# SYSCTRL_PADCONF_CORE register map
Vendor: Texas Instruments
Registers are 32-bit, access per field, reset 0x10F010F unless marked. A register's access mark holds for its fields unless they carry their own. Offsets are as the file gives them; [hi:lo] are bit positions; lines under a group give offsets from that group; {n}, {i} and the like mark numbered series; 'fields as' and 'values as' point back to an identical list.

## SYSCTRL_PADCONF_CORE (part 9 of 10)
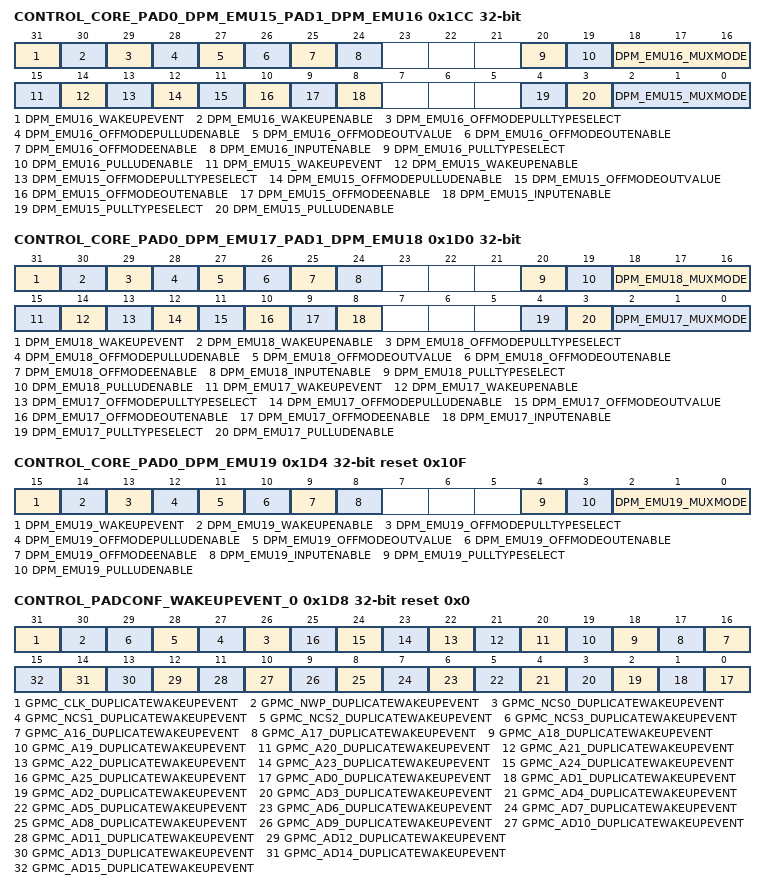
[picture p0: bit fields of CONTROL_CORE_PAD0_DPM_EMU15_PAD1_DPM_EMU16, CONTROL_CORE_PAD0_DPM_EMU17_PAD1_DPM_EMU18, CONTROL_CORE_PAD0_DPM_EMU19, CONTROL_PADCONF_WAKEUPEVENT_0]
0x1CC CONTROL_CORE_PAD0_DPM_EMU15_PAD1_DPM_EMU16 — Register control for Pads dpm_emu15 and dpm_emu16 Access conditions. Read: unrestricted, Write: unrestricted
  [31] DPM_EMU16_WAKEUPEVENT ro — Pad_x wake-up event status latched in the IO
    0=DPM_EMU16_WAKEUPEVENT_0_r (No wake-up event occurred); 1=DPM_EMU16_WAKEUPEVENT_1_r (A wake-up event occurred)
  [30] DPM_EMU16_WAKEUPENABLE rw — Input pad wake-up enable (and OFF mode input enable value)
    0=wake-up detection is disabled; 1=wake-up detection is enabled
  [29] DPM_EMU16_OFFMODEPULLTYPESELECT rw — OffMode mode pullup/down selection for pad dpm_emu16
    0=Offmode pulldown selected; 1=Offmode pullup selected
  [28] DPM_EMU16_OFFMODEPULLUDENABLE rw — OffMode mode pullup/down enable for pad dpm_emu16
    0=Offmode pullup/down disabled; 1=Offmode pullup/down enabled
  [27] DPM_EMU16_OFFMODEOUTVALUE rw — OffMode mode output value for pad dpm_emu16
    0=Set value at 0; 1=Set value at 1
  [26] DPM_EMU16_OFFMODEOUTENABLE rw — OffMode mode output enable value for pad dpm_emu16. This is an active low signal
    0=Output enable; 1=Output disable
  [25] DPM_EMU16_OFFMODEENABLE rw — OffMode mode override control for pad dpm_emu16
    0=I/O state keeps its previous state when OFF mode is active; 1=I/O state is forced to OFF mode value when OFF mode is active
  [24] DPM_EMU16_INPUTENABLE rw — Input enable value for pad dpm_emu16
    0=Input buffer of I/O cell is disabled; 1=Input buffer of I/O cell is enabled
  [20] DPM_EMU16_PULLTYPESELECT rw — pullup/down selection for pad dpm_emu16
    0=pulldown selected; 1=pullup selected
  [19] DPM_EMU16_PULLUDENABLE rw — pullup/down enable for pad dpm_emu16
    0=pullup/down disabled; 1=pullup/down enabled
  [18:16] DPM_EMU16_MUXMODE rw — Functional multiplexing selection for pad dpm_emu16
    0=Select dpm_emu16; 1=Select dmtimer8_pwm_evt; 2=Select dsi1_te0; 3=Select gpio_27; 4=Select rfbi_data3; 5=Select dispc2_data3; 6=Select hw_dbg16; 7=Select safe_mode
  [15] DPM_EMU15_WAKEUPEVENT ro — Pad_x wake-up event status latched in the IO
    0=DPM_EMU15_WAKEUPEVENT_0_r (No wake-up event occurred); 1=DPM_EMU15_WAKEUPEVENT_1_r (A wake-up event occurred)
  [14] DPM_EMU15_WAKEUPENABLE rw — Input pad wake-up enable (and OFF mode input enable value)
    values as DPM_EMU16_WAKEUPENABLE
  [13] DPM_EMU15_OFFMODEPULLTYPESELECT rw — OffMode mode pullup/down selection for pad dpm_emu15
    0=Offmode pulldown selected; 1=Offmode pullup selected
  [12] DPM_EMU15_OFFMODEPULLUDENABLE rw — OffMode mode pullup/down enable for pad dpm_emu15
    values as DPM_EMU16_OFFMODEPULLUDENABLE
  [11] DPM_EMU15_OFFMODEOUTVALUE rw — OffMode mode output value for pad dpm_emu15
    0=Set value at 0; 1=Set value at 1
  [10] DPM_EMU15_OFFMODEOUTENABLE rw — OffMode mode output enable value for pad dpm_emu15. This is an active low signal
    0=Output enable; 1=Output disable
  [9] DPM_EMU15_OFFMODEENABLE rw — OffMode mode override control for pad dpm_emu15
    values as DPM_EMU16_OFFMODEENABLE
  [8] DPM_EMU15_INPUTENABLE rw — Input enable value for pad dpm_emu15
    values as DPM_EMU16_INPUTENABLE
  [4] DPM_EMU15_PULLTYPESELECT rw — pullup/down selection for pad dpm_emu15
    0=pulldown selected; 1=pullup selected
  [3] DPM_EMU15_PULLUDENABLE rw — pullup/down enable for pad dpm_emu15
    0=pullup/down disabled; 1=pullup/down enabled
  [2:0] DPM_EMU15_MUXMODE rw — Functional multiplexing selection for pad dpm_emu15
    0=Select dpm_emu15; 3=Select gpio_26; 4=Select rfbi_data4; 5=Select dispc2_data4; 6=Select hw_dbg15; 7=Select safe_mode
0x1D0 CONTROL_CORE_PAD0_DPM_EMU17_PAD1_DPM_EMU18 — Register control for Pads dpm_emu17 and dpm_emu18 Access conditions. Read: unrestricted, Write: unrestricted
  [31] DPM_EMU18_WAKEUPEVENT ro — Pad_x wake-up event status latched in the IO
    0=DPM_EMU18_WAKEUPEVENT_0_r (No wake-up event occurred); 1=DPM_EMU18_WAKEUPEVENT_1_r (A wake-up event occurred)
  [30] DPM_EMU18_WAKEUPENABLE rw — Input pad wake-up enable (and OFF mode input enable value)
    values as CONTROL_CORE_PAD0_DPM_EMU15_PAD1_DPM_EMU16.DPM_EMU16_WAKEUPENABLE
  [29] DPM_EMU18_OFFMODEPULLTYPESELECT rw — OffMode mode pullup/down selection for pad dpm_emu18
    0=Offmode pulldown selected; 1=Offmode pullup selected
  [28] DPM_EMU18_OFFMODEPULLUDENABLE rw — OffMode mode pullup/down enable for pad dpm_emu18
    values as CONTROL_CORE_PAD0_DPM_EMU15_PAD1_DPM_EMU16.DPM_EMU16_OFFMODEPULLUDENABLE
  [27] DPM_EMU18_OFFMODEOUTVALUE rw — OffMode mode output value for pad dpm_emu18
    0=Set value at 0; 1=Set value at 1
  [26] DPM_EMU18_OFFMODEOUTENABLE rw — OffMode mode output enable value for pad dpm_emu18. This is an active low signal
    0=Output enable; 1=Output disable
  [25] DPM_EMU18_OFFMODEENABLE rw — OffMode mode override control for pad dpm_emu18
    values as CONTROL_CORE_PAD0_DPM_EMU15_PAD1_DPM_EMU16.DPM_EMU16_OFFMODEENABLE
  [24] DPM_EMU18_INPUTENABLE rw — Input enable value for pad dpm_emu18
    values as CONTROL_CORE_PAD0_DPM_EMU15_PAD1_DPM_EMU16.DPM_EMU16_INPUTENABLE
  [20] DPM_EMU18_PULLTYPESELECT rw — pullup/down selection for pad dpm_emu18
    0=pulldown selected; 1=pullup selected
  [19] DPM_EMU18_PULLUDENABLE rw — pullup/down enable for pad dpm_emu18
    0=pullup/down disabled; 1=pullup/down enabled
  [18:16] DPM_EMU18_MUXMODE rw — Functional multiplexing selection for pad dpm_emu18
    0=Select dpm_emu18; 1=Select dmtimer10_pwm_evt; 2=Select dsi2_te0; 3=Select gpio_190; 4=Select rfbi_data1; 5=Select dispc2_data1; 6=Select hw_dbg18; 7=Select safe_mode
  [15] DPM_EMU17_WAKEUPEVENT ro — Pad_x wake-up event status latched in the IO
    0=DPM_EMU17_WAKEUPEVENT_0_r (No wake-up event occurred); 1=DPM_EMU17_WAKEUPEVENT_1_r (A wake-up event occurred)
  [14] DPM_EMU17_WAKEUPENABLE rw — Input pad wake-up enable (and OFF mode input enable value)
    values as CONTROL_CORE_PAD0_DPM_EMU15_PAD1_DPM_EMU16.DPM_EMU16_WAKEUPENABLE
  [13] DPM_EMU17_OFFMODEPULLTYPESELECT rw — OffMode mode pullup/down selection for pad dpm_emu17
    0=Offmode pulldown selected; 1=Offmode pullup selected
  [12] DPM_EMU17_OFFMODEPULLUDENABLE rw — OffMode mode pullup/down enable for pad dpm_emu17
    values as CONTROL_CORE_PAD0_DPM_EMU15_PAD1_DPM_EMU16.DPM_EMU16_OFFMODEPULLUDENABLE
  [11] DPM_EMU17_OFFMODEOUTVALUE rw — OffMode mode output value for pad dpm_emu17
    0=Set value at 0; 1=Set value at 1
  [10] DPM_EMU17_OFFMODEOUTENABLE rw — OffMode mode output enable value for pad dpm_emu17. This is an active low signal
    0=Output enable; 1=Output disable
  [9] DPM_EMU17_OFFMODEENABLE rw — OffMode mode override control for pad dpm_emu17
    values as CONTROL_CORE_PAD0_DPM_EMU15_PAD1_DPM_EMU16.DPM_EMU16_OFFMODEENABLE
  [8] DPM_EMU17_INPUTENABLE rw — Input enable value for pad dpm_emu17
    values as CONTROL_CORE_PAD0_DPM_EMU15_PAD1_DPM_EMU16.DPM_EMU16_INPUTENABLE
  [4] DPM_EMU17_PULLTYPESELECT rw — pullup/down selection for pad dpm_emu17
    0=pulldown selected; 1=pullup selected
  [3] DPM_EMU17_PULLUDENABLE rw — pullup/down enable for pad dpm_emu17
    0=pullup/down disabled; 1=pullup/down enabled
  [2:0] DPM_EMU17_MUXMODE rw — Functional multiplexing selection for pad dpm_emu17
    0=Select dpm_emu17; 1=Select dmtimer9_pwm_evt; 2=Select dsi1_te1; 3=Select gpio_28; 4=Select rfbi_data2; 5=Select dispc2_data2; 6=Select hw_dbg17; 7=Select safe_mode
0x1D4 CONTROL_CORE_PAD0_DPM_EMU19 reset 0x10F — Register control for Pad dpm_emu19 Access conditions. Read: unrestricted, Write: unrestricted
  [15] DPM_EMU19_WAKEUPEVENT ro — Pad_x wake-up event status latched in the IO
    0=DPM_EMU19_WAKEUPEVENT_0_r (No wake-up event occurred); 1=DPM_EMU19_WAKEUPEVENT_1_r (A wake-up event occurred)
  [14] DPM_EMU19_WAKEUPENABLE rw — Input pad wake-up enable (and OFF mode input enable value)
    values as CONTROL_CORE_PAD0_DPM_EMU15_PAD1_DPM_EMU16.DPM_EMU16_WAKEUPENABLE
  [13] DPM_EMU19_OFFMODEPULLTYPESELECT rw — OffMode mode pullup/down selection for pad dpm_emu19
    0=Offmode pulldown selected; 1=Offmode pullup selected
  [12] DPM_EMU19_OFFMODEPULLUDENABLE rw — OffMode mode pullup/down enable for pad dpm_emu19
    values as CONTROL_CORE_PAD0_DPM_EMU15_PAD1_DPM_EMU16.DPM_EMU16_OFFMODEPULLUDENABLE
  [11] DPM_EMU19_OFFMODEOUTVALUE rw — OffMode mode output value for pad dpm_emu19
    0=Set value at 0; 1=Set value at 1
  [10] DPM_EMU19_OFFMODEOUTENABLE rw — OffMode mode output enable value for pad dpm_emu19. This is an active low signal
    0=Output enable; 1=Output disable
  [9] DPM_EMU19_OFFMODEENABLE rw — OffMode mode override control for pad dpm_emu19
    values as CONTROL_CORE_PAD0_DPM_EMU15_PAD1_DPM_EMU16.DPM_EMU16_OFFMODEENABLE
  [8] DPM_EMU19_INPUTENABLE rw — Input enable value for pad dpm_emu19
    values as CONTROL_CORE_PAD0_DPM_EMU15_PAD1_DPM_EMU16.DPM_EMU16_INPUTENABLE
  [4] DPM_EMU19_PULLTYPESELECT rw — pullup/down selection for pad dpm_emu19
    0=pulldown selected; 1=pullup selected
  [3] DPM_EMU19_PULLUDENABLE rw — pullup/down enable for pad dpm_emu19
    0=pullup/down disabled; 1=pullup/down enabled
  [2:0] DPM_EMU19_MUXMODE rw — Functional multiplexing selection for pad dpm_emu19
    0=Select dpm_emu19; 1=Select dmtimer11_pwm_evt; 2=Select dsi2_te1; 3=Select gpio_191; 4=Select rfbi_data0; 5=Select dispc2_data0; 6=Select hw_dbg19; 7=Select safe_mode
0x1D8 CONTROL_PADCONF_WAKEUPEVENT_0 ro reset 0x0 — Access conditions. Read: unrestricted, Write: unrestricted
  [31] GPMC_CLK_DUPLICATEWAKEUPEVENT — Wake-up event status latched in the I/O for pad gpmc_clk
    0=GPMC_CLK_DUPLICATEWAKEUPEVENT_0_r (No wake-up event occurred); 1=GPMC_CLK_DUPLICATEWAKEUPEVENT_1_r (A wake-up event occurred)
  [30] GPMC_NWP_DUPLICATEWAKEUPEVENT — Wake-up event status latched in the I/O for pad gpmc_nwp
    0=GPMC_NWP_DUPLICATEWAKEUPEVENT_0_r (No wake-up event occurred); 1=GPMC_NWP_DUPLICATEWAKEUPEVENT_1_r (A wake-up event occurred)
  [n+26] GPMC_NCS{n}_DUPLICATEWAKEUPEVENT (n=0..3) — Wake-up event status latched in the I/O for pad gpmc_ncs{n}
    0=GPMC_NCS{n}_DUPLICATEWAKEUPEVENT_0_r (No wake-up event occurred); 1=GPMC_NCS{n}_DUPLICATEWAKEUPEVENT_1_r (A wake-up event occurred)
  [n] GPMC_A{n}_DUPLICATEWAKEUPEVENT (n=16..25) — Wake-up event status latched in the I/O for pad gpmc_a{n}
    0=GPMC_A{n}_DUPLICATEWAKEUPEVENT_0_r (No wake-up event occurred); 1=GPMC_A{n}_DUPLICATEWAKEUPEVENT_1_r (A wake-up event occurred)
  [n] GPMC_AD{n}_DUPLICATEWAKEUPEVENT (n=0..15) — Wake-up event status latched in the I/O for pad gpmc_ad{n}
    0=GPMC_AD{n}_DUPLICATEWAKEUPEVENT_0_r (No wake-up event occurred); 1=GPMC_AD{n}_DUPLICATEWAKEUPEVENT_1_r (A wake-up event occurred)
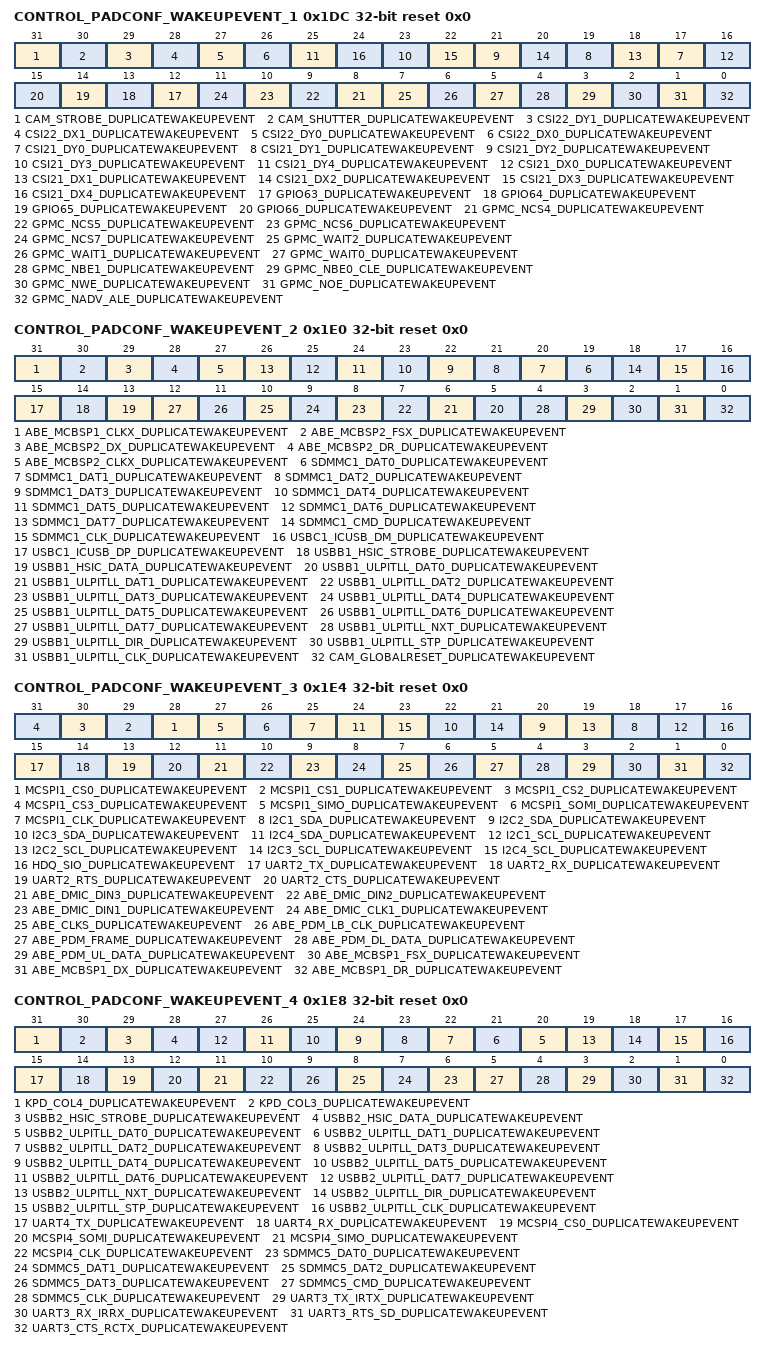
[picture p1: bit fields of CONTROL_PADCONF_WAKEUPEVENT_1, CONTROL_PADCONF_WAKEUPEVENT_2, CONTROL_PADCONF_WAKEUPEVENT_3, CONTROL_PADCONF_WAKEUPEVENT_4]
0x1DC CONTROL_PADCONF_WAKEUPEVENT_1 ro reset 0x0 — Access conditions. Read: unrestricted, Write: unrestricted
  [31] CAM_STROBE_DUPLICATEWAKEUPEVENT — Wake-up event status latched in the I/O for pad cam_strobe
    0=CAM_STROBE_DUPLICATEWAKEUPEVENT_0_r (No wake-up event occurred); 1=CAM_STROBE_DUPLICATEWAKEUPEVENT_1_r (A wake-up event occurred)
  [30] CAM_SHUTTER_DUPLICATEWAKEUPEVENT — Wake-up event status latched in the I/O for pad cam_shutter
    0=CAM_SHUTTER_DUPLICATEWAKEUPEVENT_0_r (No wake-up event occurred); 1=CAM_SHUTTER_DUPLICATEWAKEUPEVENT_1_r (A wake-up event occurred)
  [29] CSI22_DY1_DUPLICATEWAKEUPEVENT — Wake-up event status latched in the I/O for pad csi22_dy1
    0=CSI22_DY1_DUPLICATEWAKEUPEVENT_0_r (No wake-up event occurred); 1=CSI22_DY1_DUPLICATEWAKEUPEVENT_1_r (A wake-up event occurred)
  [28] CSI22_DX1_DUPLICATEWAKEUPEVENT — Wake-up event status latched in the I/O for pad csi22_dx1
    0=CSI22_DX1_DUPLICATEWAKEUPEVENT_0_r (No wake-up event occurred); 1=CSI22_DX1_DUPLICATEWAKEUPEVENT_1_r (A wake-up event occurred)
  [27] CSI22_DY0_DUPLICATEWAKEUPEVENT — Wake-up event status latched in the I/O for pad csi22_dy0
    0=CSI22_DY0_DUPLICATEWAKEUPEVENT_0_r (No wake-up event occurred); 1=CSI22_DY0_DUPLICATEWAKEUPEVENT_1_r (A wake-up event occurred)
  [26] CSI22_DX0_DUPLICATEWAKEUPEVENT — Wake-up event status latched in the I/O for pad csi22_dx0
    0=CSI22_DX0_DUPLICATEWAKEUPEVENT_0_r (No wake-up event occurred); 1=CSI22_DX0_DUPLICATEWAKEUPEVENT_1_r (A wake-up event occurred)
  [2n+17] CSI21_DY{n}_DUPLICATEWAKEUPEVENT (n=0..4) — Wake-up event status latched in the I/O for pad csi21_dy{n}
    0=CSI21_DY{n}_DUPLICATEWAKEUPEVENT_0_r (No wake-up event occurred); 1=CSI21_DY{n}_DUPLICATEWAKEUPEVENT_1_r (A wake-up event occurred)
  [2n+16] CSI21_DX{n}_DUPLICATEWAKEUPEVENT (n=0..4) — Wake-up event status latched in the I/O for pad csi21_dx{n}
    0=CSI21_DX{n}_DUPLICATEWAKEUPEVENT_0_r (No wake-up event occurred); 1=CSI21_DX{n}_DUPLICATEWAKEUPEVENT_1_r (A wake-up event occurred)
  [n-51] GPIO{n}_DUPLICATEWAKEUPEVENT (n=63..66) — Wake-up event status latched in the I/O for pad gpio{n}
    0=GPIO{n}_DUPLICATEWAKEUPEVENT_0_r (No wake-up event occurred); 1=GPIO{n}_DUPLICATEWAKEUPEVENT_1_r (A wake-up event occurred)
  [n+4] GPMC_NCS{n}_DUPLICATEWAKEUPEVENT (n=4..7) — Wake-up event status latched in the I/O for pad gpmc_ncs{n}
    values as CONTROL_PADCONF_WAKEUPEVENT_0.GPMC_NCS0_DUPLICATEWAKEUPEVENT
  [7] GPMC_WAIT2_DUPLICATEWAKEUPEVENT — Wake-up event status latched in the I/O for pad gpmc_wait2
    0=GPMC_WAIT2_DUPLICATEWAKEUPEVENT_0_r (No wake-up event occurred); 1=GPMC_WAIT2_DUPLICATEWAKEUPEVENT_1_r (A wake-up event occurred)
  [6] GPMC_WAIT1_DUPLICATEWAKEUPEVENT — Wake-up event status latched in the I/O for pad gpmc_wait1
    0=GPMC_WAIT1_DUPLICATEWAKEUPEVENT_0_r (No wake-up event occurred); 1=GPMC_WAIT1_DUPLICATEWAKEUPEVENT_1_r (A wake-up event occurred)
  [5] GPMC_WAIT0_DUPLICATEWAKEUPEVENT — Wake-up event status latched in the I/O for pad gpmc_wait0
    0=GPMC_WAIT0_DUPLICATEWAKEUPEVENT_0_r (No wake-up event occurred); 1=GPMC_WAIT0_DUPLICATEWAKEUPEVENT_1_r (A wake-up event occurred)
  [4] GPMC_NBE1_DUPLICATEWAKEUPEVENT — Wake-up event status latched in the I/O for pad gpmc_nbe1
    0=GPMC_NBE1_DUPLICATEWAKEUPEVENT_0_r (No wake-up event occurred); 1=GPMC_NBE1_DUPLICATEWAKEUPEVENT_1_r (A wake-up event occurred)
  [3] GPMC_NBE0_CLE_DUPLICATEWAKEUPEVENT — Wake-up event status latched in the I/O for pad gpmc_nbe0_cle
    0=GPMC_NBE0_CLE_DUPLICATEWAKEUPEVENT_0_r (No wake-up event occurred); 1=GPMC_NBE0_CLE_DUPLICATEWAKEUPEVENT_1_r (A wake-up event occurred)
  [2] GPMC_NWE_DUPLICATEWAKEUPEVENT — Wake-up event status latched in the I/O for pad gpmc_nwe
    0=GPMC_NWE_DUPLICATEWAKEUPEVENT_0_r (No wake-up event occurred); 1=GPMC_NWE_DUPLICATEWAKEUPEVENT_1_r (A wake-up event occurred)
  [1] GPMC_NOE_DUPLICATEWAKEUPEVENT — Wake-up event status latched in the I/O for pad gpmc_noe
    0=GPMC_NOE_DUPLICATEWAKEUPEVENT_0_r (No wake-up event occurred); 1=GPMC_NOE_DUPLICATEWAKEUPEVENT_1_r (A wake-up event occurred)
  [0] GPMC_NADV_ALE_DUPLICATEWAKEUPEVENT — Wake-up event status latched in the I/O for pad gpmc_nadv_ale
    0=GPMC_NADV_ALE_DUPLICATEWAKEUPEVENT_0_r (No wake-up event occurred); 1=GPMC_NADV_ALE_DUPLICATEWAKEUPEVENT_1_r (A wake-up event occurred)
0x1E0 CONTROL_PADCONF_WAKEUPEVENT_2 ro reset 0x0 — Access conditions. Read: unrestricted, Write: unrestricted
  [31] ABE_MCBSP1_CLKX_DUPLICATEWAKEUPEVENT — Wake-up event status latched in the I/O for pad abe_mcbsp1_clkx
    0=ABE_MCBSP1_CLKX_DUPLICATEWAKEUPEVENT_0_r (No wake-up event occurred); 1=ABE_MCBSP1_CLKX_DUPLICATEWAKEUPEVENT_1_r (A wake-up event occurred)
  [30] ABE_MCBSP2_FSX_DUPLICATEWAKEUPEVENT — Wake-up event status latched in the I/O for pad abe_mcbsp2_fsx
    0=ABE_MCBSP2_FSX_DUPLICATEWAKEUPEVENT_0_r (No wake-up event occurred); 1=ABE_MCBSP2_FSX_DUPLICATEWAKEUPEVENT_1_r (A wake-up event occurred)
  [29] ABE_MCBSP2_DX_DUPLICATEWAKEUPEVENT — Wake-up event status latched in the I/O for pad abe_mcbsp2_dx
    0=ABE_MCBSP2_DX_DUPLICATEWAKEUPEVENT_0_r (No wake-up event occurred); 1=ABE_MCBSP2_DX_DUPLICATEWAKEUPEVENT_1_r (A wake-up event occurred)
  [28] ABE_MCBSP2_DR_DUPLICATEWAKEUPEVENT — Wake-up event status latched in the I/O for pad abe_mcbsp2_dr
    0=ABE_MCBSP2_DR_DUPLICATEWAKEUPEVENT_0_r (No wake-up event occurred); 1=ABE_MCBSP2_DR_DUPLICATEWAKEUPEVENT_1_r (A wake-up event occurred)
  [27] ABE_MCBSP2_CLKX_DUPLICATEWAKEUPEVENT — Wake-up event status latched in the I/O for pad abe_mcbsp2_clkx
    0=ABE_MCBSP2_CLKX_DUPLICATEWAKEUPEVENT_0_r (No wake-up event occurred); 1=ABE_MCBSP2_CLKX_DUPLICATEWAKEUPEVENT_1_r (A wake-up event occurred)
  [n+19] SDMMC1_DAT{n}_DUPLICATEWAKEUPEVENT (n=0..7) — Wake-up event status latched in the I/O for pad sdmmc1_dat{n}
    0=SDMMC1_DAT{n}_DUPLICATEWAKEUPEVENT_0_r (No wake-up event occurred); 1=SDMMC1_DAT{n}_DUPLICATEWAKEUPEVENT_1_r (A wake-up event occurred)
  [18] SDMMC1_CMD_DUPLICATEWAKEUPEVENT — Wake-up event status latched in the I/O for pad sdmmc1_cmd
    0=SDMMC1_CMD_DUPLICATEWAKEUPEVENT_0_r (No wake-up event occurred); 1=SDMMC1_CMD_DUPLICATEWAKEUPEVENT_1_r (A wake-up event occurred)
  [17] SDMMC1_CLK_DUPLICATEWAKEUPEVENT — Wake-up event status latched in the I/O for pad sdmmc1_clk
    0=SDMMC1_CLK_DUPLICATEWAKEUPEVENT_0_r (No wake-up event occurred); 1=SDMMC1_CLK_DUPLICATEWAKEUPEVENT_1_r (A wake-up event occurred)
  [16] USBC1_ICUSB_DM_DUPLICATEWAKEUPEVENT — Wake-up event status latched in the I/O for pad usbc1_icusb_dm
    0=USBC1_ICUSB_DM_DUPLICATEWAKEUPEVENT_0_r (No wake-up event occurred); 1=USBC1_ICUSB_DM_DUPLICATEWAKEUPEVENT_1_r (A wake-up event occurred)
  [15] USBC1_ICUSB_DP_DUPLICATEWAKEUPEVENT — Wake-up event status latched in the I/O for pad usbc1_icusb_dp
    0=USBC1_ICUSB_DP_DUPLICATEWAKEUPEVENT_0_r (No wake-up event occurred); 1=USBC1_ICUSB_DP_DUPLICATEWAKEUPEVENT_1_r (A wake-up event occurred)
  [14] USBB1_HSIC_STROBE_DUPLICATEWAKEUPEVENT — Wake-up event status latched in the I/O for pad usbb1_hsic_strobe
    0=USBB1_HSIC_STROBE_DUPLICATEWAKEUPEVENT_0_r (No wake-up event occurred); 1=USBB1_HSIC_STROBE_DUPLICATEWAKEUPEVENT_1_r (A wake-up event occurred)
  [13] USBB1_HSIC_DATA_DUPLICATEWAKEUPEVENT — Wake-up event status latched in the I/O for pad usbb1_hsic_data
    0=USBB1_HSIC_DATA_DUPLICATEWAKEUPEVENT_0_r (No wake-up event occurred); 1=USBB1_HSIC_DATA_DUPLICATEWAKEUPEVENT_1_r (A wake-up event occurred)
  [n+5] USBB1_ULPITLL_DAT{n}_DUPLICATEWAKEUPEVENT (n=0..7) — Wake-up event status latched in the I/O for pad usbb1_ulpitll_dat{n}
    0=USBB1_ULPITLL_DAT{n}_DUPLICATEWAKEUPEVENT_0_r (No wake-up event occurred); 1=USBB1_ULPITLL_DAT{n}_DUPLICATEWAKEUPEVENT_1_r (A wake-up event occurred)
  [4] USBB1_ULPITLL_NXT_DUPLICATEWAKEUPEVENT — Wake-up event status latched in the I/O for pad usbb1_ulpitll_nxt
    0=USBB1_ULPITLL_NXT_DUPLICATEWAKEUPEVENT_0_r (No wake-up event occurred); 1=USBB1_ULPITLL_NXT_DUPLICATEWAKEUPEVENT_1_r (A wake-up event occurred)
  [3] USBB1_ULPITLL_DIR_DUPLICATEWAKEUPEVENT — Wake-up event status latched in the I/O for pad usbb1_ulpitll_dir
    0=USBB1_ULPITLL_DIR_DUPLICATEWAKEUPEVENT_0_r (No wake-up event occurred); 1=USBB1_ULPITLL_DIR_DUPLICATEWAKEUPEVENT_1_r (A wake-up event occurred)
  [2] USBB1_ULPITLL_STP_DUPLICATEWAKEUPEVENT — Wake-up event status latched in the I/O for pad usbb1_ulpitll_stp
    0=USBB1_ULPITLL_STP_DUPLICATEWAKEUPEVENT_0_r (No wake-up event occurred); 1=USBB1_ULPITLL_STP_DUPLICATEWAKEUPEVENT_1_r (A wake-up event occurred)
  [1] USBB1_ULPITLL_CLK_DUPLICATEWAKEUPEVENT — Wake-up event status latched in the I/O for pad usbb1_ulpitll_clk
    0=USBB1_ULPITLL_CLK_DUPLICATEWAKEUPEVENT_0_r (No wake-up event occurred); 1=USBB1_ULPITLL_CLK_DUPLICATEWAKEUPEVENT_1_r (A wake-up event occurred)
  [0] CAM_GLOBALRESET_DUPLICATEWAKEUPEVENT — Wake-up event status latched in the I/O for pad cam_globalreset
    0=CAM_GLOBALRESET_DUPLICATEWAKEUPEVENT_0_r (No wake-up event occurred); 1=CAM_GLOBALRESET_DUPLICATEWAKEUPEVENT_1_r (A wake-up event occurred)
0x1E4 CONTROL_PADCONF_WAKEUPEVENT_3 ro reset 0x0 — Access conditions. Read: unrestricted, Write: unrestricted
  [n+28] MCSPI1_CS{n}_DUPLICATEWAKEUPEVENT (n=0..3) — Wake-up event status latched in the I/O for pad mcspi1_cs{n}
    0=MCSPI1_CS{n}_DUPLICATEWAKEUPEVENT_0_r (No wake-up event occurred); 1=MCSPI1_CS{n}_DUPLICATEWAKEUPEVENT_1_r (A wake-up event occurred)
  [27] MCSPI1_SIMO_DUPLICATEWAKEUPEVENT — Wake-up event status latched in the I/O for pad mcspi1_simo
    0=MCSPI1_SIMO_DUPLICATEWAKEUPEVENT_0_r (No wake-up event occurred); 1=MCSPI1_SIMO_DUPLICATEWAKEUPEVENT_1_r (A wake-up event occurred)
  [26] MCSPI1_SOMI_DUPLICATEWAKEUPEVENT — Wake-up event status latched in the I/O for pad mcspi1_somi
    0=MCSPI1_SOMI_DUPLICATEWAKEUPEVENT_0_r (No wake-up event occurred); 1=MCSPI1_SOMI_DUPLICATEWAKEUPEVENT_1_r (A wake-up event occurred)
  [25] MCSPI1_CLK_DUPLICATEWAKEUPEVENT — Wake-up event status latched in the I/O for pad mcspi1_clk
    0=MCSPI1_CLK_DUPLICATEWAKEUPEVENT_0_r (No wake-up event occurred); 1=MCSPI1_CLK_DUPLICATEWAKEUPEVENT_1_r (A wake-up event occurred)
  [2n+16] I2C{n}_SDA_DUPLICATEWAKEUPEVENT (n=1..4) — Wake-up event status latched in the I/O for pad i2c{n}_sda
    0=I2C{n}_SDA_DUPLICATEWAKEUPEVENT_0_r (No wake-up event occurred); 1=I2C{n}_SDA_DUPLICATEWAKEUPEVENT_1_r (A wake-up event occurred)
  [2n+15] I2C{n}_SCL_DUPLICATEWAKEUPEVENT (n=1..4) — Wake-up event status latched in the I/O for pad i2c{n}_scl
    0=I2C{n}_SCL_DUPLICATEWAKEUPEVENT_0_r (No wake-up event occurred); 1=I2C{n}_SCL_DUPLICATEWAKEUPEVENT_1_r (A wake-up event occurred)
  [16] HDQ_SIO_DUPLICATEWAKEUPEVENT — Wake-up event status latched in the I/O for pad hdq_sio
    0=HDQ_SIO_DUPLICATEWAKEUPEVENT_0_r (No wake-up event occurred); 1=HDQ_SIO_DUPLICATEWAKEUPEVENT_1_r (A wake-up event occurred)
  [15] UART2_TX_DUPLICATEWAKEUPEVENT — Wake-up event status latched in the I/O for pad uart2_tx
    0=UART2_TX_DUPLICATEWAKEUPEVENT_0_r (No wake-up event occurred); 1=UART2_TX_DUPLICATEWAKEUPEVENT_1_r (A wake-up event occurred)
  [14] UART2_RX_DUPLICATEWAKEUPEVENT — Wake-up event status latched in the I/O for pad uart2_rx
    0=UART2_RX_DUPLICATEWAKEUPEVENT_0_r (No wake-up event occurred); 1=UART2_RX_DUPLICATEWAKEUPEVENT_1_r (A wake-up event occurred)
  [13] UART2_RTS_DUPLICATEWAKEUPEVENT — Wake-up event status latched in the I/O for pad uart2_rts
    0=UART2_RTS_DUPLICATEWAKEUPEVENT_0_r (No wake-up event occurred); 1=UART2_RTS_DUPLICATEWAKEUPEVENT_1_r (A wake-up event occurred)
  [12] UART2_CTS_DUPLICATEWAKEUPEVENT — Wake-up event status latched in the I/O for pad uart2_cts
    0=UART2_CTS_DUPLICATEWAKEUPEVENT_0_r (No wake-up event occurred); 1=UART2_CTS_DUPLICATEWAKEUPEVENT_1_r (A wake-up event occurred)
  [11] ABE_DMIC_DIN3_DUPLICATEWAKEUPEVENT — Wake-up event status latched in the I/O for pad abe_dmic_din3
    0=ABE_DMIC_DIN3_DUPLICATEWAKEUPEVENT_0_r (No wake-up event occurred); 1=ABE_DMIC_DIN3_DUPLICATEWAKEUPEVENT_1_r (A wake-up event occurred)
  [10] ABE_DMIC_DIN2_DUPLICATEWAKEUPEVENT — Wake-up event status latched in the I/O for pad abe_dmic_din2
    0=ABE_DMIC_DIN2_DUPLICATEWAKEUPEVENT_0_r (No wake-up event occurred); 1=ABE_DMIC_DIN2_DUPLICATEWAKEUPEVENT_1_r (A wake-up event occurred)
  [9] ABE_DMIC_DIN1_DUPLICATEWAKEUPEVENT — Wake-up event status latched in the I/O for pad abe_dmic_din1
    0=ABE_DMIC_DIN1_DUPLICATEWAKEUPEVENT_0_r (No wake-up event occurred); 1=ABE_DMIC_DIN1_DUPLICATEWAKEUPEVENT_1_r (A wake-up event occurred)
  [8] ABE_DMIC_CLK1_DUPLICATEWAKEUPEVENT — Wake-up event status latched in the I/O for pad abe_dmic_clk1
    0=ABE_DMIC_CLK1_DUPLICATEWAKEUPEVENT_0_r (No wake-up event occurred); 1=ABE_DMIC_CLK1_DUPLICATEWAKEUPEVENT_1_r (A wake-up event occurred)
  [7] ABE_CLKS_DUPLICATEWAKEUPEVENT — Wake-up event status latched in the I/O for pad abe_clks
    0=ABE_CLKS_DUPLICATEWAKEUPEVENT_0_r (No wake-up event occurred); 1=ABE_CLKS_DUPLICATEWAKEUPEVENT_1_r (A wake-up event occurred)
  [6] ABE_PDM_LB_CLK_DUPLICATEWAKEUPEVENT — Wake-up event status latched in the I/O for pad abe_pdm_lb_clk
    0=ABE_PDM_LB_CLK_DUPLICATEWAKEUPEVENT_0_r (No wake-up event occurred); 1=ABE_PDM_LB_CLK_DUPLICATEWAKEUPEVENT_1_r (A wake-up event occurred)
  [5] ABE_PDM_FRAME_DUPLICATEWAKEUPEVENT — Wake-up event status latched in the I/O for pad abe_pdm_frame
    0=ABE_PDM_FRAME_DUPLICATEWAKEUPEVENT_0_r (No wake-up event occurred); 1=ABE_PDM_FRAME_DUPLICATEWAKEUPEVENT_1_r (A wake-up event occurred)
  [4] ABE_PDM_DL_DATA_DUPLICATEWAKEUPEVENT — Wake-up event status latched in the I/O for pad abe_pdm_dl_data
    0=ABE_PDM_DL_DATA_DUPLICATEWAKEUPEVENT_0_r (No wake-up event occurred); 1=ABE_PDM_DL_DATA_DUPLICATEWAKEUPEVENT_1_r (A wake-up event occurred)
  [3] ABE_PDM_UL_DATA_DUPLICATEWAKEUPEVENT — Wake-up event status latched in the I/O for pad abe_pdm_ul_data
    0=ABE_PDM_UL_DATA_DUPLICATEWAKEUPEVENT_0_r (No wake-up event occurred); 1=ABE_PDM_UL_DATA_DUPLICATEWAKEUPEVENT_1_r (A wake-up event occurred)
  [2] ABE_MCBSP1_FSX_DUPLICATEWAKEUPEVENT — Wake-up event status latched in the I/O for pad abe_mcbsp1_fsx
    0=ABE_MCBSP1_FSX_DUPLICATEWAKEUPEVENT_0_r (No wake-up event occurred); 1=ABE_MCBSP1_FSX_DUPLICATEWAKEUPEVENT_1_r (A wake-up event occurred)
  [1] ABE_MCBSP1_DX_DUPLICATEWAKEUPEVENT — Wake-up event status latched in the I/O for pad abe_mcbsp1_dx
    0=ABE_MCBSP1_DX_DUPLICATEWAKEUPEVENT_0_r (No wake-up event occurred); 1=ABE_MCBSP1_DX_DUPLICATEWAKEUPEVENT_1_r (A wake-up event occurred)
  [0] ABE_MCBSP1_DR_DUPLICATEWAKEUPEVENT — Wake-up event status latched in the I/O for pad abe_mcbsp1_dr
    0=ABE_MCBSP1_DR_DUPLICATEWAKEUPEVENT_0_r (No wake-up event occurred); 1=ABE_MCBSP1_DR_DUPLICATEWAKEUPEVENT_1_r (A wake-up event occurred)
0x1E8 CONTROL_PADCONF_WAKEUPEVENT_4 ro reset 0x0 — Access conditions. Read: unrestricted, Write: unrestricted
  [31] KPD_COL4_DUPLICATEWAKEUPEVENT — Wake-up event status latched in the I/O for pad kpd_col4
    0=KPD_COL4_DUPLICATEWAKEUPEVENT_0_r (No wake-up event occurred); 1=KPD_COL4_DUPLICATEWAKEUPEVENT_1_r (A wake-up event occurred)
  [30] KPD_COL3_DUPLICATEWAKEUPEVENT — Wake-up event status latched in the I/O for pad kpd_col3
    0=KPD_COL3_DUPLICATEWAKEUPEVENT_0_r (No wake-up event occurred); 1=KPD_COL3_DUPLICATEWAKEUPEVENT_1_r (A wake-up event occurred)
  [29] USBB2_HSIC_STROBE_DUPLICATEWAKEUPEVENT — Wake-up event status latched in the I/O for pad usbb2_hsic_strobe
    0=USBB2_HSIC_STROBE_DUPLICATEWAKEUPEVENT_0_r (No wake-up event occurred); 1=USBB2_HSIC_STROBE_DUPLICATEWAKEUPEVENT_1_r (A wake-up event occurred)
  [28] USBB2_HSIC_DATA_DUPLICATEWAKEUPEVENT — Wake-up event status latched in the I/O for pad usbb2_hsic_data
    0=USBB2_HSIC_DATA_DUPLICATEWAKEUPEVENT_0_r (No wake-up event occurred); 1=USBB2_HSIC_DATA_DUPLICATEWAKEUPEVENT_1_r (A wake-up event occurred)
  [n+20] USBB2_ULPITLL_DAT{n}_DUPLICATEWAKEUPEVENT (n=0..7) — Wake-up event status latched in the I/O for pad usbb2_ulpitll_dat{n}
    0=USBB2_ULPITLL_DAT{n}_DUPLICATEWAKEUPEVENT_0_r (No wake-up event occurred); 1=USBB2_ULPITLL_DAT{n}_DUPLICATEWAKEUPEVENT_1_r (A wake-up event occurred)
  [19] USBB2_ULPITLL_NXT_DUPLICATEWAKEUPEVENT — Wake-up event status latched in the I/O for pad usbb2_ulpitll_nxt
    0=USBB2_ULPITLL_NXT_DUPLICATEWAKEUPEVENT_0_r (No wake-up event occurred); 1=USBB2_ULPITLL_NXT_DUPLICATEWAKEUPEVENT_1_r (A wake-up event occurred)
  [18] USBB2_ULPITLL_DIR_DUPLICATEWAKEUPEVENT — Wake-up event status latched in the I/O for pad usbb2_ulpitll_dir
    0=USBB2_ULPITLL_DIR_DUPLICATEWAKEUPEVENT_0_r (No wake-up event occurred); 1=USBB2_ULPITLL_DIR_DUPLICATEWAKEUPEVENT_1_r (A wake-up event occurred)
  [17] USBB2_ULPITLL_STP_DUPLICATEWAKEUPEVENT — Wake-up event status latched in the I/O for pad usbb2_ulpitll_stp
    0=USBB2_ULPITLL_STP_DUPLICATEWAKEUPEVENT_0_r (No wake-up event occurred); 1=USBB2_ULPITLL_STP_DUPLICATEWAKEUPEVENT_1_r (A wake-up event occurred)
  [16] USBB2_ULPITLL_CLK_DUPLICATEWAKEUPEVENT — Wake-up event status latched in the I/O for pad usbb2_ulpitll_clk
    0=USBB2_ULPITLL_CLK_DUPLICATEWAKEUPEVENT_0_r (No wake-up event occurred); 1=USBB2_ULPITLL_CLK_DUPLICATEWAKEUPEVENT_1_r (A wake-up event occurred)
  [15] UART4_TX_DUPLICATEWAKEUPEVENT — Wake-up event status latched in the I/O for pad uart4_tx
    0=UART4_TX_DUPLICATEWAKEUPEVENT_0_r (No wake-up event occurred); 1=UART4_TX_DUPLICATEWAKEUPEVENT_1_r (A wake-up event occurred)
  [14] UART4_RX_DUPLICATEWAKEUPEVENT — Wake-up event status latched in the I/O for pad uart4_rx
    0=UART4_RX_DUPLICATEWAKEUPEVENT_0_r (No wake-up event occurred); 1=UART4_RX_DUPLICATEWAKEUPEVENT_1_r (A wake-up event occurred)
  [13] MCSPI4_CS0_DUPLICATEWAKEUPEVENT — Wake-up event status latched in the I/O for pad mcspi4_cs0
    0=MCSPI4_CS0_DUPLICATEWAKEUPEVENT_0_r (No wake-up event occurred); 1=MCSPI4_CS0_DUPLICATEWAKEUPEVENT_1_r (A wake-up event occurred)
  [12] MCSPI4_SOMI_DUPLICATEWAKEUPEVENT — Wake-up event status latched in the I/O for pad mcspi4_somi
    0=MCSPI4_SOMI_DUPLICATEWAKEUPEVENT_0_r (No wake-up event occurred); 1=MCSPI4_SOMI_DUPLICATEWAKEUPEVENT_1_r (A wake-up event occurred)
  [11] MCSPI4_SIMO_DUPLICATEWAKEUPEVENT — Wake-up event status latched in the I/O for pad mcspi4_simo
    0=MCSPI4_SIMO_DUPLICATEWAKEUPEVENT_0_r (No wake-up event occurred); 1=MCSPI4_SIMO_DUPLICATEWAKEUPEVENT_1_r (A wake-up event occurred)
  [10] MCSPI4_CLK_DUPLICATEWAKEUPEVENT — Wake-up event status latched in the I/O for pad mcspi4_clk
    0=MCSPI4_CLK_DUPLICATEWAKEUPEVENT_0_r (No wake-up event occurred); 1=MCSPI4_CLK_DUPLICATEWAKEUPEVENT_1_r (A wake-up event occurred)
  [n+6] SDMMC5_DAT{n}_DUPLICATEWAKEUPEVENT (n=0..3) — Wake-up event status latched in the I/O for pad sdmmc5_dat{n}
    0=SDMMC5_DAT{n}_DUPLICATEWAKEUPEVENT_0_r (No wake-up event occurred); 1=SDMMC5_DAT{n}_DUPLICATEWAKEUPEVENT_1_r (A wake-up event occurred)
  [5] SDMMC5_CMD_DUPLICATEWAKEUPEVENT — Wake-up event status latched in the I/O for pad sdmmc5_cmd
    0=SDMMC5_CMD_DUPLICATEWAKEUPEVENT_0_r (No wake-up event occurred); 1=SDMMC5_CMD_DUPLICATEWAKEUPEVENT_1_r (A wake-up event occurred)
  [4] SDMMC5_CLK_DUPLICATEWAKEUPEVENT — Wake-up event status latched in the I/O for pad sdmmc5_clk
    0=SDMMC5_CLK_DUPLICATEWAKEUPEVENT_0_r (No wake-up event occurred); 1=SDMMC5_CLK_DUPLICATEWAKEUPEVENT_1_r (A wake-up event occurred)
  [3] UART3_TX_IRTX_DUPLICATEWAKEUPEVENT — Wake-up event status latched in the I/O for pad uart3_tx_irtx
    0=UART3_TX_IRTX_DUPLICATEWAKEUPEVENT_0_r (No wake-up event occurred); 1=UART3_TX_IRTX_DUPLICATEWAKEUPEVENT_1_r (A wake-up event occurred)
  [2] UART3_RX_IRRX_DUPLICATEWAKEUPEVENT — Wake-up event status latched in the I/O for pad uart3_rx_irrx
    0=UART3_RX_IRRX_DUPLICATEWAKEUPEVENT_0_r (No wake-up event occurred); 1=UART3_RX_IRRX_DUPLICATEWAKEUPEVENT_1_r (A wake-up event occurred)
  [1] UART3_RTS_SD_DUPLICATEWAKEUPEVENT — Wake-up event status latched in the I/O for pad uart3_rts_sd
    0=UART3_RTS_SD_DUPLICATEWAKEUPEVENT_0_r (No wake-up event occurred); 1=UART3_RTS_SD_DUPLICATEWAKEUPEVENT_1_r (A wake-up event occurred)
  [0] UART3_CTS_RCTX_DUPLICATEWAKEUPEVENT — Wake-up event status latched in the I/O for pad uart3_cts_rctx
    0=UART3_CTS_RCTX_DUPLICATEWAKEUPEVENT_0_r (No wake-up event occurred); 1=UART3_CTS_RCTX_DUPLICATEWAKEUPEVENT_1_r (A wake-up event occurred)
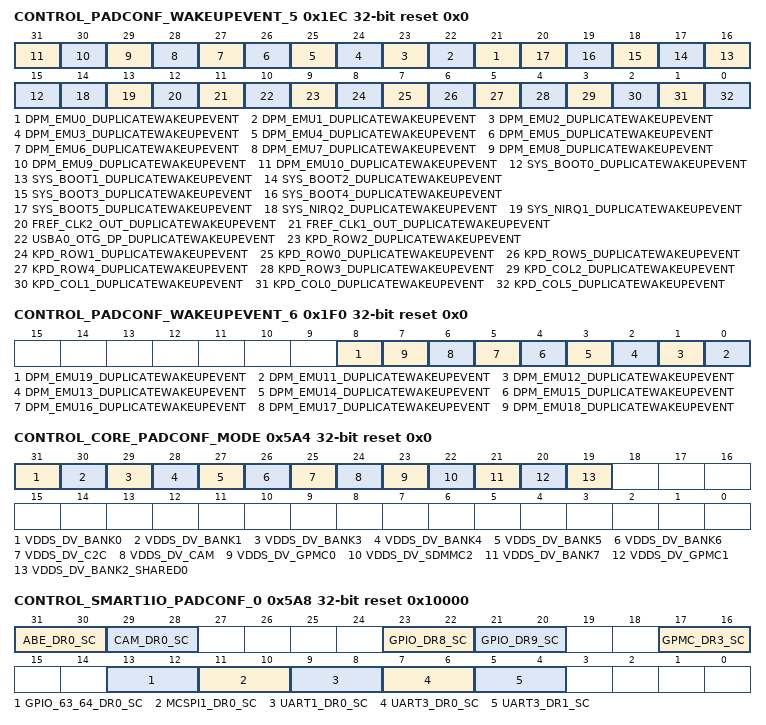
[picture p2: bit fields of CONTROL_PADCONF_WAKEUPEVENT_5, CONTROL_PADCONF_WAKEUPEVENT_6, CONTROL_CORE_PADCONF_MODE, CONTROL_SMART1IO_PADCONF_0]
0x1EC CONTROL_PADCONF_WAKEUPEVENT_5 ro reset 0x0 — Access conditions. Read: unrestricted, Write: unrestricted
  [n+21] DPM_EMU{n}_DUPLICATEWAKEUPEVENT (n=0..10) — Wake-up event status latched in the I/O for pad dpm_emu{n}
    0=DPM_EMU{n}_DUPLICATEWAKEUPEVENT_0_r (No wake-up event occurred); 1=DPM_EMU{n}_DUPLICATEWAKEUPEVENT_1_r (A wake-up event occurred)
  [n+15] SYS_BOOT{n}_DUPLICATEWAKEUPEVENT (n=0..5) — Wake-up event status latched in the I/O for pad sys_boot{n}
    0=SYS_BOOT{n}_DUPLICATEWAKEUPEVENT_0_r (No wake-up event occurred); 1=SYS_BOOT{n}_DUPLICATEWAKEUPEVENT_1_r (A wake-up event occurred)
  [14] SYS_NIRQ2_DUPLICATEWAKEUPEVENT — Wake-up event status latched in the I/O for pad sys_nirq2
    0=SYS_NIRQ2_DUPLICATEWAKEUPEVENT_0_r (No wake-up event occurred); 1=SYS_NIRQ2_DUPLICATEWAKEUPEVENT_1_r (A wake-up event occurred)
  [13] SYS_NIRQ1_DUPLICATEWAKEUPEVENT — Wake-up event status latched in the I/O for pad sys_nirq1
    0=SYS_NIRQ1_DUPLICATEWAKEUPEVENT_0_r (No wake-up event occurred); 1=SYS_NIRQ1_DUPLICATEWAKEUPEVENT_1_r (A wake-up event occurred)
  [12] FREF_CLK2_OUT_DUPLICATEWAKEUPEVENT — Wake-up event status latched in the I/O for pad fref_clk2_out
    0=FREF_CLK2_OUT_DUPLICATEWAKEUPEVENT_0_r (No wake-up event occurred); 1=FREF_CLK2_OUT_DUPLICATEWAKEUPEVENT_1_r (A wake-up event occurred)
  [11] FREF_CLK1_OUT_DUPLICATEWAKEUPEVENT — Wake-up event status latched in the I/O for pad fref_clk1_out
    0=FREF_CLK1_OUT_DUPLICATEWAKEUPEVENT_0_r (No wake-up event occurred); 1=FREF_CLK1_OUT_DUPLICATEWAKEUPEVENT_1_r (A wake-up event occurred)
  [10] USBA0_OTG_DP_DUPLICATEWAKEUPEVENT — Wake-up event status latched in the I/O for pad usba0_otg_dp
    0=USBA0_OTG_DP_DUPLICATEWAKEUPEVENT_0_r (No wake-up event occurred); 1=USBA0_OTG_DP_DUPLICATEWAKEUPEVENT_1_r (A wake-up event occurred)
  [9] KPD_ROW2_DUPLICATEWAKEUPEVENT — Wake-up event status latched in the I/O for pad kpd_row2
    0=KPD_ROW2_DUPLICATEWAKEUPEVENT_0_r (No wake-up event occurred); 1=KPD_ROW2_DUPLICATEWAKEUPEVENT_1_r (A wake-up event occurred)
  [8] KPD_ROW1_DUPLICATEWAKEUPEVENT — Wake-up event status latched in the I/O for pad kpd_row1
    0=KPD_ROW1_DUPLICATEWAKEUPEVENT_0_r (No wake-up event occurred); 1=KPD_ROW1_DUPLICATEWAKEUPEVENT_1_r (A wake-up event occurred)
  [7] KPD_ROW0_DUPLICATEWAKEUPEVENT — Wake-up event status latched in the I/O for pad kpd_row0
    0=KPD_ROW0_DUPLICATEWAKEUPEVENT_0_r (No wake-up event occurred); 1=KPD_ROW0_DUPLICATEWAKEUPEVENT_1_r (A wake-up event occurred)
  [6] KPD_ROW5_DUPLICATEWAKEUPEVENT — Wake-up event status latched in the I/O for pad kpd_row5
    0=KPD_ROW5_DUPLICATEWAKEUPEVENT_0_r (No wake-up event occurred); 1=KPD_ROW5_DUPLICATEWAKEUPEVENT_1_r (A wake-up event occurred)
  [5] KPD_ROW4_DUPLICATEWAKEUPEVENT — Wake-up event status latched in the I/O for pad kpd_row4
    0=KPD_ROW4_DUPLICATEWAKEUPEVENT_0_r (No wake-up event occurred); 1=KPD_ROW4_DUPLICATEWAKEUPEVENT_1_r (A wake-up event occurred)
  [4] KPD_ROW3_DUPLICATEWAKEUPEVENT — Wake-up event status latched in the I/O for pad kpd_row3
    0=KPD_ROW3_DUPLICATEWAKEUPEVENT_0_r (No wake-up event occurred); 1=KPD_ROW3_DUPLICATEWAKEUPEVENT_1_r (A wake-up event occurred)
  [3] KPD_COL2_DUPLICATEWAKEUPEVENT — Wake-up event status latched in the I/O for pad kpd_col2
    0=KPD_COL2_DUPLICATEWAKEUPEVENT_0_r (No wake-up event occurred); 1=KPD_COL2_DUPLICATEWAKEUPEVENT_1_r (A wake-up event occurred)
  [2] KPD_COL1_DUPLICATEWAKEUPEVENT — Wake-up event status latched in the I/O for pad kpd_col1
    0=KPD_COL1_DUPLICATEWAKEUPEVENT_0_r (No wake-up event occurred); 1=KPD_COL1_DUPLICATEWAKEUPEVENT_1_r (A wake-up event occurred)
  [1] KPD_COL0_DUPLICATEWAKEUPEVENT — Wake-up event status latched in the I/O for pad kpd_col0
    0=KPD_COL0_DUPLICATEWAKEUPEVENT_0_r (No wake-up event occurred); 1=KPD_COL0_DUPLICATEWAKEUPEVENT_1_r (A wake-up event occurred)
  [0] KPD_COL5_DUPLICATEWAKEUPEVENT — Wake-up event status latched in the I/O for pad kpd_col5
    0=KPD_COL5_DUPLICATEWAKEUPEVENT_0_r (No wake-up event occurred); 1=KPD_COL5_DUPLICATEWAKEUPEVENT_1_r (A wake-up event occurred)
0x1F0 CONTROL_PADCONF_WAKEUPEVENT_6 ro reset 0x0 — Access conditions. Read: unrestricted, Write: unrestricted
  [8] DPM_EMU19_DUPLICATEWAKEUPEVENT — Wake-up event status latched in the IO for pad dpm_emu19
    1=DPM_EMU19_DUPLICATEWAKEUPEVENT_1_r (A wakeup event occurred); 0=DPM_EMU19_DUPLICATEWAKEUPEVENT_0_r (No wakeup event occurred)
  [n-11] DPM_EMU{n}_DUPLICATEWAKEUPEVENT (n=11..18) — Wake-up event status latched in the I/O for pad dpm_emu{n}
    values as CONTROL_PADCONF_WAKEUPEVENT_5.DPM_EMU0_DUPLICATEWAKEUPEVENT
0x5A0 CONTROL_PADCONF_GLOBAL reset 0x0 — Global PAD control Access conditions. Read: unrestricted, Write: unrestricted
  [31] FORCE_OFFMODE_EN rw — Force offmode enable for PADs
    0=Offmode is not forced active; 1=Offmode is forced active
0x5A4 CONTROL_CORE_PADCONF_MODE reset 0x0 — PAD Voltage Mode control Access conditions. Read: unrestricted, Write: unrestricted
  [all] fields
    0=VDDS = 1.8V; 1=VDDS = 1.2V
  [31] VDDS_DV_BANK0 rw — PAD Voltage level control for vdds_dv_bank0
  [30] VDDS_DV_BANK1 rw — PAD Voltage level control for vdds_dv_bank1
  [32-n] VDDS_DV_BANK{n} rw (n=3..6) — PAD Voltage level control for vdds_dv_bank{n}
  [25] VDDS_DV_C2C rw — PAD Voltage level control for vdds_dv_c2c
  [24] VDDS_DV_CAM rw — PAD Voltage level control for vdds_dv_cam
  [23] VDDS_DV_GPMC0 rw — PAD Voltage level control for vdds_dv_gpmc0
  [22] VDDS_DV_SDMMC2 rw — PAD Voltage level control for vdds_dv_sdmmc2
  [21] VDDS_DV_BANK7 rw — PAD Voltage level control for vdds_dv_bank7
  [20] VDDS_DV_GPMC1 rw — PAD Voltage level control for vdds_dv_gpmc1
  [19] VDDS_DV_BANK2_SHARED0 rw — PAD Voltage level control for vdds_dv_bank2_shared0
0x5A8 CONTROL_SMART1IO_PADCONF_0 rw reset 0x10000 — SMART1 I/O control 0 Access conditions. Read: unrestricted, Write: unrestricted
  [31:30] ABE_DR0_SC — Slew rate control for group abe_dr0. Refer to , section Low Speed I/Os Combined Slew Rate vs TL Length and Load Settings for more details on SR settings.
  [29:28] CAM_DR0_SC — Slew rate control for group cam_dr0. Refer to , section Low Speed I/Os Combined Slew Rate vs TL Length and Load Settings for more details on SR settings.
  [23:22] GPIO_DR8_SC — Slew rate control for group gpio_dr8. Refer to , section Low Speed I/Os Combined Slew Rate vs TL Length and Load Settings for more details on SR settings.
  [21:20] GPIO_DR9_SC — Slew rate control for group gpio_dr9. Refer to , section Low Speed I/Os Combined Slew Rate vs TL Length and Load Settings for more details on SR settings.
  [17:16] GPMC_DR3_SC — Slew rate control for group gpmc_dr3. Refer to , section Low Speed I/Os Combined Slew Rate vs TL Length and Load Settings for more details on SR settings.
  [13:12] GPIO_63_64_DR0_SC — Slew rate control for group gpio_63_64_dr0. Refer to , section Low Speed I/Os Combined Slew Rate vs TL Length and Load Settings for more details on SR settings.
  [11:10] MCSPI1_DR0_SC — Slew rate control for group mcspi1_dr0 Refer to , section Low Speed I/Os Combined Slew Rate vs TL Length and Load Settings for more details on SR settings.
  [9:8] UART1_DR0_SC — Slew rate control for group uart1_dr0 Refer to , section Low Speed I/Os Combined Slew Rate vs TL Length and Load Settings for more details on SR settings.
  [7:6] UART3_DR0_SC — Slew rate control for group uart3_dr0 Refer to , section Low Speed I/Os Combined Slew Rate vs TL Length and Load Settings for more details on SR settings.
  [5:4] UART3_DR1_SC — Slew rate control for group uart3_dr1 Refer to , section Low Speed I/Os Combined Slew Rate vs TL Length and Load Settings for more details on SR settings.
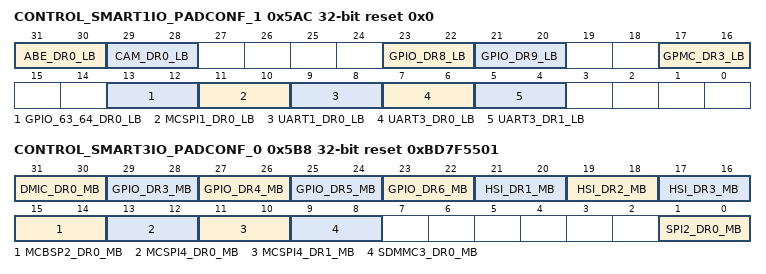
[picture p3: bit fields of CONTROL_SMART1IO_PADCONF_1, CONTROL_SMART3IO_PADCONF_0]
0x5AC CONTROL_SMART1IO_PADCONF_1 rw reset 0x0 — SMART1 I/O control 1 Access conditions. Read: unrestricted, Write: unrestricted
  [all] fields
    0=TL Length= [2cm-20cm] / Farend cap per TL= [1pF-10pF]; 1=Dual TL Length= [20cm-40cm] / Farend cap per TL= [1pF-10pF]; 2=TL Length = [2cm-20cm] / Farend cap per TL= [10pF-20pF]; 3=Dual TL Length = [20cm-40cm] / Farend cap per TL= [10pF-20pF]
  [31:30] ABE_DR0_LB — Load control for group abe_dr0
  [29:28] CAM_DR0_LB — Load control for group cam_dr0
  [23:22] GPIO_DR8_LB — Load control for group gpio_dr8
  [21:20] GPIO_DR9_LB — Load control for group gpio_dr9
  [17:16] GPMC_DR3_LB — Load control for group gpmc_dr3
  [13:12] GPIO_63_64_DR0_LB — Load control for group gpio_63_64_dr0
  [11:10] MCSPI1_DR0_LB — Load control for group mcspi1_dr0
  [9:8] UART1_DR0_LB — Load control for group uart1_dr0
  [7:6] UART3_DR0_LB — Load control for group uart3_dr0
  [5:4] UART3_DR1_LB — Load control for group uart3_dr1
0x5B0 CONTROL_SMART2IO_PADCONF_0 rw reset 0x0 — SMART2 I/O control 0 Access conditions. Read: unrestricted, Write: unrestricted
0x5B4 CONTROL_SMART2IO_PADCONF_1 ro reset 0x0 — SMART2 I/O control 1 Access conditions. Read: unrestricted, Write: unrestricted
0x5B8 CONTROL_SMART3IO_PADCONF_0 reset 0xBD7F5501 — SMART3 I/O control 0 Access conditions. Read: unrestricted, Write: unrestricted
  [31:30] DMIC_DR0_MB rw — 50-Ω output buffer mode control for group dmic_dr0. Refer to 50-Ω output buffer I/Os with combined Mode and Load Settings for more details on mode settings.
  [29:28] GPIO_DR3_MB rw — 25-Ω output buffer mode control for group gpio_dr3. Refer to I/Os with combined Mode and Load Settings for more details on mode settings.
  [27:26] GPIO_DR4_MB rw — 25-Ω output buffer mode control for group gpio_dr4. Refer to I/Os with combined Mode and Load Settings for more details on mode settings.
  [25:24] GPIO_DR5_MB rw — 50-Ω output buffer mode control for group gpio_dr5. Refer to 50-Ω output buffer I/Os with combined Mode and Load Settings for more details on mode settings.
  [23:22] GPIO_DR6_MB rw — 50-Ω output buffer mode control for group gpio_dr6. Refer to 50-Ω output buffer I/Os with combined Mode and Load Settings for more details on mode settings.
  [21:20] HSI_DR1_MB rw — 25-Ω output buffer mode control for group hsi_dr1. Refer to the I/Os with combined Mode and Load Settings for more information about mode settings.
  [19:18] HSI_DR2_MB rw — 25-Ω output buffer mode control for group hsi_dr2. Refer to the I/Os with combined Mode and Load Settings for more information about mode settings.
  [17:16] HSI_DR3_MB rw — 25-Ω output buffer mode control for group hsi_dr3. Refer to I/Os with combined Mode and Load Settings for more details on mode settings.
  [15:14] MCBSP2_DR0_MB rw — 50-Ω output buffer mode control for group mcbsp2_dr0. Refer to 50-Ω output buffer I/Os with combined Mode and Load Settings for more details on mode settings.
  [13:12] MCSPI4_DR0_MB rw — 50-Ω output buffer mode control for group mcspi4_dr0. Refer to 50-Ω output buffer I/Os with combined Mode and Load Settings for more details on mode settings.
  [11:10] MCSPI4_DR1_MB rw — 50-Ω output buffer mode control for group mcspi4_dr1. Refer to 50-Ω output buffer I/Os with combined Mode and Load Settings for more details on mode settings.
  [9:8] SDMMC3_DR0_MB rw — 50-Ω output buffer mode control for group sdmmc3_dr0. Refer to 50-Ω output buffer I/Os with combined Mode and Load Settings for more details on mode settings.
  [1:0] SPI2_DR0_MB rw — 50-Ω output buffer mode control for group spi2_dr0. Refer to 50-Ω output buffer I/Os with combined Mode and Load Settings for more details on mode settings.
